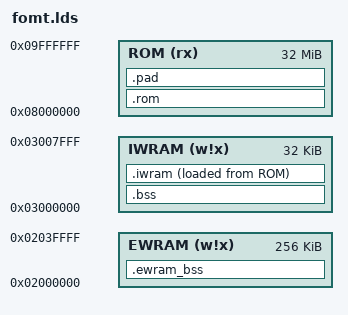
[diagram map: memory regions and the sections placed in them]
OUTPUT_ARCH(arm)

_M4aNumMusicPlayers = 5;
_M4aMaxLines = 0x50;

gMPlayJumpTableTemplate = 0x08139A88;
gScaleTable = 0x08139B18;
gFreqTable = 0x08139BCC;
gPcmSamplesPerVBlankTable = 0x08139BFC;
gCgbScaleTable = 0x08139C14;
gCgbFreqTable = 0x08139C98;
gNoiseTable = 0x08139CB0;
gCgb3Vol = 0x08139CEC;
gClockTable = 0x08139CFC;
gXcmdTable = 0x08139D30;

__15ControllerC7F58Pv = func_080C7F58;
_._15ControllerC7F58 = func_080C8360;
__vt_19LivestockController = vtable_unk_080E7D30;
func_08085584 = __19LivestockControllerPvUi;
func_0808562C = _._19LivestockController;

func_0805218C = __15SceneOwner521BCRt8SmartPtr1Z13AUnk_0800080CPv;
func_08057DD8 = __15SceneOwner57E1CRt8SmartPtr1Z13AUnk_0800080CPvUc;
func_0805CEB8 = __15SceneOwner5CEFCRt8SmartPtr1Z13AUnk_0800080CPvUc;
func_0805E624 = __15SceneOwner5E658Rt8SmartPtr1Z13AUnk_0800080CPv;
func_08069E14 = __15SceneOwner69E58Rt8SmartPtr1Z13AUnk_0800080CPvUc;
func_0805FCD0 = __15SceneOwner5FD04Rt8SmartPtr1Z13AUnk_0800080CPv;
func_080755EC = __15SceneOwner7561CRt8SmartPtr1Z13AUnk_0800080CPv;
func_0807DD38 = __15SceneOwner7DD68Rt8SmartPtr1Z13AUnk_0800080CPv;
func_0807EE14 = __15SceneOwner7EE44Rt8SmartPtr1Z13AUnk_0800080CPv;
func_0807F580 = __15SceneOwner7F5B0Rt8SmartPtr1Z13AUnk_0800080CPv;
func_0808045C = __15SceneOwner8048CRt8SmartPtr1Z13AUnk_0800080CPv;
func_08080D94 = __15SceneOwner80DC4Rt8SmartPtr1Z13AUnk_0800080CPv;
func_08081A40 = __15SceneOwner81A70Rt8SmartPtr1Z13AUnk_0800080CPv;
func_08082114 = __15SceneOwner82144Rt8SmartPtr1Z13AUnk_0800080CPv;
func_08083A7C = __15SceneOwner83AECRt8SmartPtr1Z13AUnk_0800080CPvUcUiUiUiUi;
func_080854F4 = __15SceneOwner85528Rt8SmartPtr1Z13AUnk_0800080CPv;
func_08088168 = __15SceneOwner881ACRt8SmartPtr1Z13AUnk_0800080CPvUi;
func_0808AB38 = __15SceneOwner8AB68Rt8SmartPtr1Z13AUnk_0800080CPv;
func_0808C56C = __15SceneOwner8C59CRt8SmartPtr1Z13AUnk_0800080CPv;
func_0808ECD8 = __15SceneOwner8ED08Rt8SmartPtr1Z13AUnk_0800080CPv;
func_08090E54 = __15SceneOwner90E84Rt8SmartPtr1Z13AUnk_0800080CPv;
func_080931B0 = __15SceneOwner931E0Rt8SmartPtr1Z13AUnk_0800080CPv;
func_08093A58 = __15SceneOwner93A88Rt8SmartPtr1Z13AUnk_0800080CPv;
func_0809A4D4 = __15SceneOwner9A518Rt8SmartPtr1Z13AUnk_0800080CPvUc;

__vt_15SceneOwner521BC = vtable_unk_080E7934;
func_080521BC = _._15SceneOwner521BC;
Run__15SceneOwner521BC = func_080521FC;
__vt_15SceneOwner57E1C = vtable_unk_080E7960;
func_08057E1C = _._15SceneOwner57E1C;
Run__15SceneOwner57E1C = func_08057E5C;
__vt_15SceneOwner5CEFC = vtable_unk_080E798C;
func_0805CEFC = _._15SceneOwner5CEFC;
Run__15SceneOwner5CEFC = func_0805CF3C;
__vt_15SceneOwner5E658 = vtable_unk_080E79B8;
func_0805E658 = _._15SceneOwner5E658;
Run__15SceneOwner5E658 = func_0805E698;
__vt_15SceneOwner5FD04 = vtable_unk_080E79F8;
func_0805FD04 = _._15SceneOwner5FD04;
Run__15SceneOwner5FD04 = func_0805FD44;
__vt_15SceneOwner69E58 = vtable_unk_080E7A98;
func_08069E58 = _._15SceneOwner69E58;
Run__15SceneOwner69E58 = func_08069E98;
__vt_15SceneOwner7561C = vtable_unk_080E7B4C;
func_0807561C = _._15SceneOwner7561C;
Run__15SceneOwner7561C = func_0807565C;
__vt_15SceneOwner7DD68 = vtable_unk_080E7C30;
func_0807DD68 = _._15SceneOwner7DD68;
Run__15SceneOwner7DD68 = func_0807DDA8;
__vt_15SceneOwner7EE44 = vtable_unk_080E7C4C;
func_0807EE44 = _._15SceneOwner7EE44;
Run__15SceneOwner7EE44 = func_0807EE84;
__vt_15SceneOwner7F5B0 = vtable_unk_080E7C68;
func_0807F5B0 = _._15SceneOwner7F5B0;
Run__15SceneOwner7F5B0 = func_0807F5F0;
__vt_15SceneOwner8048C = vtable_unk_080E7C84;
func_0808048C = _._15SceneOwner8048C;
Run__15SceneOwner8048C = func_080804CC;
__vt_15SceneOwner80DC4 = vtable_unk_080E7CA0;
func_08080DC4 = _._15SceneOwner80DC4;
Run__15SceneOwner80DC4 = func_08080E04;
__vt_15SceneOwner81A70 = vtable_unk_080E7CBC;
func_08081A70 = _._15SceneOwner81A70;
Run__15SceneOwner81A70 = func_08081AB0;
__vt_15SceneOwner82144 = vtable_unk_080E7CD8;
func_08082144 = _._15SceneOwner82144;
Run__15SceneOwner82144 = func_08082184;
__vt_15SceneOwner83AEC = vtable_unk_080E7D04;
func_08083AEC = _._15SceneOwner83AEC;
Run__15SceneOwner83AEC = func_08083B2C;
__vt_15SceneOwner85528 = vtable_unk_080E7D20;
func_08085528 = _._15SceneOwner85528;
Run__15SceneOwner85528 = func_08085568;
__vt_15SceneOwner881AC = vtable_unk_080E7D3C;
func_080881AC = _._15SceneOwner881AC;
Run__15SceneOwner881AC = func_080881EC;
__vt_15SceneOwner8AB68 = vtable_unk_080E7D58;
func_0808AB68 = _._15SceneOwner8AB68;
Run__15SceneOwner8AB68 = func_0808ABA8;
__vt_15SceneOwner8C59C = vtable_unk_080E7D74;
func_0808C59C = _._15SceneOwner8C59C;
Run__15SceneOwner8C59C = func_0808C5DC;
__vt_15SceneOwner8ED08 = vtable_unk_080E7D90;
func_0808ED08 = _._15SceneOwner8ED08;
Run__15SceneOwner8ED08 = func_0808ED48;
__vt_15SceneOwner90E84 = vtable_unk_080E7DAC;
func_08090E84 = _._15SceneOwner90E84;
Run__15SceneOwner90E84 = func_08090EC4;
__vt_15SceneOwner925C4 = vtable_unk_080E7DC8;
func_080925C4 = _._15SceneOwner925C4;
Run__15SceneOwner925C4 = func_08092604;
__vt_15SceneOwner931E0 = vtable_unk_080E7DE4;
func_080931E0 = _._15SceneOwner931E0;
Run__15SceneOwner931E0 = func_08093220;
__vt_15SceneOwner93A88 = vtable_unk_080E8018;
func_08093A88 = _._15SceneOwner93A88;
Run__15SceneOwner93A88 = func_08093AD4;
__vt_15SceneOwner9A518 = vtable_unk_080E824C;
func_0809A518 = _._15SceneOwner9A518;
Run__15SceneOwner9A518 = func_0809A558;

__vt_7UnkPoly = vtable_unk_080E82D8;
__vt_18MenuGlyphCacheBase = vtable_unk_080E7908;
__vt_15MenuParsePolicy = vtable_unk_080E78F0;
func_080E105C = _._22MenuGlyphCacheLifetime;
func_080E10E0 = DestroyMenuCallback;
func_080E10EC = ContinueParsing__15MenuParsePolicy;
func_080E10F0 = AcceptCommand__15MenuParsePolicy;
func_080E10F4 = StopOnBoundary__15MenuParsePolicy;
func_080E10F8 = _._15MenuParsePolicy;
func_080E1118 = RowsDirty__18MenuGlyphCacheBase;
func_080E111C = Clear__18MenuGlyphCacheBase;
func_080E1120 = Next__18MenuGlyphCacheBase;
func_080E1124 = Reset__18MenuGlyphCacheBase;
func_080E1128 = _._18MenuGlyphCacheBase;
func_080E1148 = DestroyMenuScene5143C;
func_080E118C = BuildMenuArticleName;
func_080E1498 = DestroyMenuArticleProvider;
func_080E14B8 = BuildAnimalNameText;
func_080E1824 = DestroyAnimalNameProvider;
func_080E1844 = BuildIndexedItemName;
func_080E1964 = DestroyIndexedItemNameProvider;
func_080E1984 = DestroySpriteAnimationProviderLifetime;
func_080E19A4 = BuildStoredStringName;
func_080E1A28 = DestroyStoredStringNameProvider;
func_080E1A48 = RunProviderCheck;
func_080E1A54 = CleanupLargeProvider;
func_080E1C18 = DestroyMenuDualRangeCleanup;
func_080E1D54 = DestroyMenuSingleRangeCleanup;
func_080E1DBC = CheckMenuRangeProvider;
func_080E1DC8 = ReleaseMenuRangeProvider;
func_080E1DD4 = DestroyMenuRangeOwnerE1DD4;
func_080E211C = DestroyMenuRangeOwnerE211C;
func_080E2170 = RotateMenuTreeLeft;
func_080E21A8 = RotateMenuTreeRight;
func_080E21E0 = BalanceMenuTreeAfterInsert;
func_080E2354 = PreviousMenuTreeNode;
func_080E2B5C = ReleaseMenuTreeSubtreeA;
func_080E2B88 = ReleaseMenuTreeSubtreeB;
func_080E2E78 = ReleaseMenuTreeSubtreeC;
func_080D3ED4 = DestroyMenuSimple_080d3ed4;
func_080DE220 = DestroyMenuSimple_080de220;
func_080E103C = DestroyMenuSimple_080e103c;
func_080E3D94 = DestroyMenuSimple_080e3d94;
func_080E4190 = DestroyMenuSimple_080e4190;
func_080E4544 = DestroyMenuSimple_080e4544;
func_080D6F1C = InitializeMenuPair_080d6f1c;
func_080D6F5C = InitializeMenuPair_080d6f5c;
func_080D7F60 = ReleaseMenuResource_080d7f60;
func_080D7F74 = ReleaseMenuResource_080d7f74;
func_080D7F88 = ReleaseMenuResource_080d7f88;
func_080D7AAC = DestroyMenuGlobal_080d7aac;
func_080D7B04 = DestroyMenuGlobal_080d7b04;
func_080E581C = DestroyMenuGlobal_080e581c;
func_080E5844 = DestroyMenuGlobal_080e5844;
func_080DCE60 = DestroyMenuOwner_080dce60;
func_080DCEEC = DestroyMenuOwner_080dceec;
func_080E4510 = DestroyMenuOwner_080e4510;
func_080DCE94 = DestroyMenuEntity_080dce94;
func_080DCEC0 = DestroyMenuEntity_080dcec0;
func_080DCF20 = DestroyMenuEntity_080dcf20;
func_080E35E8 = InitializeMenuSubobject_080e35e8;
func_080E3628 = InitializeMenuSubobject_080e3628;
func_080E3650 = InitializeMenuSubobject_080e3650;
func_080E3734 = InitializeMenuSubobject_080e3734;
func_080DD3A8 = EmitMenuObject_080dd3a8;
func_080DD434 = EmitMenuObject_080dd434;
func_080DD514 = EmitMenuObject_080dd514;
func_080DD5B8 = EmitMenuObject_080dd5b8;
func_080DD7B8 = EmitMenuObject_080dd7b8;
func_080DD890 = EmitMenuObject_080dd890;
func_080DDE98 = EmitMenuObject_080dde98;
func_080DDF3C = EmitMenuObject_080ddf3c;
func_080DDFE0 = EmitMenuObject_080ddfe0;
func_080DE080 = EmitMenuObject_080de080;
func_080DC57C = ReleaseTreeSubtreeDC57C;
func_080E54C4 = ReleaseTreeSubtreeE54C4;
func_08007874 = __13UnkHandleBase;
func_080079E8 = _._13UnkHandleBase;
func_0803AC78 = _._12Unk_0803AB30;
func_0803B0A8 = _._12Unk_0803AEA0;
func_080A47B4 = _._7UnkPoly;
__vt_18UnknownEntityThing = vtable_unk_080E68B4;
__vt_22UnknownEntityThingBase = vtable_unk_080E65E0;
_._18UnknownEntityThing = func_080DC8F8;
__vt_12LilliaEntity = vtable_unk_080E7198;
func_08035AFC = __12LilliaEntityP10GameObjectP3NpcUi;
func_08035B38 = vfunc_30__12LilliaEntity;

__vt_10RickEntity = vtable_unk_080E7158;
func_08035B64 = __10RickEntityP10GameObjectP3NpcUi;
func_08035B9C = vfunc_30__10RickEntity;
__vt_12PopuriEntity = vtable_unk_080E7118;
func_08035BC8 = __12PopuriEntityP10GameObjectP3NpcUi;
func_08035CD4 = vfunc_30__12PopuriEntity;
__vt_12BarleyEntity = vtable_unk_080E70D8;
func_08035D04 = __12BarleyEntityP10GameObjectP3NpcUi;
func_08035D40 = vfunc_30__12BarleyEntity;
__vt_9MayEntity = vtable_unk_080E7098;
func_08035D70 = __9MayEntityP10GameObjectP3NpcUi;
func_08035DAC = vfunc_30__9MayEntity;
__vt_13SaibaraEntity = vtable_unk_080E7058;
func_08035DD8 = __13SaibaraEntityP10GameObjectP3NpcUi;
func_08035E14 = vfunc_30__13SaibaraEntity;
__vt_10GrayEntity = vtable_unk_080E7018;
func_08035E40 = __10GrayEntityP10GameObjectP3NpcUi;
func_08035E7C = vfunc_30__10GrayEntity;
__vt_10DukeEntity = vtable_unk_080E6FD8;
func_08035EAC = __10DukeEntityP10GameObjectP3NpcUi;
func_08035EE4 = vfunc_30__10DukeEntity;
__vt_11MannaEntity = vtable_unk_080E6F98;
func_08035F10 = __11MannaEntityP10GameObjectP3NpcUi;
func_08035F48 = vfunc_30__11MannaEntity;
__vt_11BasilEntity = vtable_unk_080E6F58;
func_08035F74 = __11BasilEntityP10GameObjectP3NpcUi;
func_08035FB0 = vfunc_30__11BasilEntity;
__vt_10AnnaEntity = vtable_unk_080E6F18;
func_08035FE0 = __10AnnaEntityP10GameObjectP3NpcUi;
func_0803601C = vfunc_30__10AnnaEntity;
__vt_10MaryEntity = vtable_unk_080E6ED8;
func_08036048 = __10MaryEntityP10GameObjectP3NpcUi;
func_08036154 = vfunc_30__10MaryEntity;
__vt_12ThomasEntity = vtable_unk_080E6E98;
func_08036184 = __12ThomasEntityP10GameObjectP3NpcUi;
func_080361C0 = vfunc_30__12ThomasEntity;
__vt_12HarrisEntity = vtable_unk_080E6E58;
func_080361EC = __12HarrisEntityP10GameObjectP3NpcUi;
func_08036228 = vfunc_30__12HarrisEntity;
__vt_11EllenEntity = vtable_unk_080E6E18;
func_08036258 = __11EllenEntityP10GameObjectP3NpcUi;
func_08036290 = vfunc_30__11EllenEntity;
__vt_9StuEntity = vtable_unk_080E6DD8;
func_080362C0 = __9StuEntityP10GameObjectP3NpcUi;
func_080362FC = vfunc_30__9StuEntity;
__vt_10JeffEntity = vtable_unk_080E6D98;
func_08036328 = __10JeffEntityP10GameObjectP3NpcUi;
func_08036364 = vfunc_30__10JeffEntity;
__vt_11SashaEntity = vtable_unk_080E6D58;
func_08036390 = __11SashaEntityP10GameObjectP3NpcUi;
func_080363CC = vfunc_30__11SashaEntity;
__vt_11KarenEntity = vtable_unk_080E6D18;
func_080363F8 = __11KarenEntityP10GameObjectP3NpcUi;
func_08036500 = vfunc_30__11KarenEntity;
__vt_12DoctorEntity = vtable_unk_080E6CD8;
func_08036530 = __12DoctorEntityP10GameObjectP3NpcUi;
func_08036564 = vfunc_30__12DoctorEntity;
__vt_10ElliEntity = vtable_unk_080E6C98;
func_08036590 = __10ElliEntityP10GameObjectP3NpcUi;
func_0803669C = vfunc_30__10ElliEntity;
__vt_12CarterEntity = vtable_unk_080E6C58;
func_080366CC = __12CarterEntityP10GameObjectP3NpcUi;
func_08036704 = vfunc_30__12CarterEntity;
__vt_11CliffEntity = vtable_unk_080E6C18;
func_08036730 = __11CliffEntityP10GameObjectP3NpcUi;
func_080367C8 = vfunc_30__11CliffEntity;
__vt_10DougEntity = vtable_unk_080E6BD8;
func_080367F8 = __10DougEntityP10GameObjectP3NpcUi;
func_08036834 = vfunc_30__10DougEntity;
__vt_9AnnEntity = vtable_unk_080E6B58;
func_080368C4 = __9AnnEntityP10GameObjectP3NpcUi;
func_080369E0 = vfunc_30__9AnnEntity;
__vt_9KaiEntity = vtable_unk_080E6B18;
func_08036A10 = __9KaiEntityP10GameObjectP3NpcUi;
func_08036A4C = vfunc_30__9KaiEntity;
__vt_10GotzEntity = vtable_unk_080E6AD8;
func_08036A78 = __10GotzEntityP10GameObjectP3NpcUi;
func_08036B1C = vfunc_30__10GotzEntity;
__vt_10ZackEntity = vtable_unk_080E6A98;
func_08036B4C = __10ZackEntityP10GameObjectP3NpcUi;
func_08036B80 = vfunc_30__10ZackEntity;
__vt_9WonEntity = vtable_unk_080E6A58;
func_08036C48 = __9WonEntityP10GameObjectP3NpcUi;
func_08036C80 = vfunc_30__9WonEntity;
__vt_13GourmetEntity = vtable_unk_080E6A18;
func_08036CAC = __13GourmetEntityP10GameObjectP3NpcUi;
func_08036CDC = vfunc_30__13GourmetEntity;
__vt_20HarvestGoddessEntity = vtable_unk_080E69D8;
func_08036D0C = __20HarvestGoddessEntityP10GameObjectP3NpcUi;
func_08036D3C = vfunc_30__20HarvestGoddessEntity;
__vt_11KappaEntity = vtable_unk_080E6998;
func_08036D68 = __11KappaEntityP10GameObjectP3NpcUi;
func_08036D98 = vfunc_30__11KappaEntity;
__vt_8LuEntity = vtable_unk_080E6B98;
func_08036860 = __8LuEntityP10GameObjectP3NpcUi;
func_08036898 = vfunc_30__8LuEntity;

__vt_9LouEntity = vtable_unk_080E6958;
func_08036DC4 = __9LouEntityP10GameObjectP3NpcUi;
func_08036E00 = vfunc_30__9LouEntity;
__vt_11ChildEntity = vtable_unk_080E6918;
func_08036E2C = __11ChildEntityP10GameObjectP3NpcUi;
func_08036EF0 = vfunc_3C__11ChildEntityUi;

__vt_14UnkEntity37008 = vtable_unk_080E7328;
func_08037008 = __14UnkEntity37008P10GameObjectR13ActorLocationUiUi;
func_08037048 = _._14UnkEntity37008;
func_08037244 = SetBox__14UnkEntity37008RC3Box;
func_08037430 = vfunc_34__14UnkEntity37008;
func_08037434 = vfunc_10__14UnkEntity37008;
func_0803745C = vfunc_14__14UnkEntity37008;
func_08037470 = GetBox__C14UnkEntity37008;

__vt_13UnkEntity72E4 = vtable_unk_080E72E4;
func_0803753C = vfunc_30__13UnkEntity72E4;
__vt_13UnkEntity72A0 = vtable_unk_080E72A0;
func_080376E4 = vfunc_30__13UnkEntity72A0;
__vt_13UnkEntity725C = vtable_unk_080E725C;
func_0803788C = vfunc_30__13UnkEntity725C;
func_080378B8 = vfunc_3C__13UnkEntity725C;
func_080378EC = GetAnim__13UnkEntity725CUi;
__vt_13UnkEntity7218 = vtable_unk_080E7218;
func_080379D8 = vfunc_30__13UnkEntity7218;
func_08037A04 = vfunc_3C__13UnkEntity7218;
func_08037A38 = GetAnim__13UnkEntity7218Ui;
func_08037618 = GetAnim__13UnkEntity72E4Ui;
func_08037628 = GetSpeed__13UnkEntity72E4Ui;
func_080377C4 = GetAnim__13UnkEntity72A0Ui;
func_080377D4 = GetSpeed__13UnkEntity72A0Ui;
func_080378FC = GetSpeed__13UnkEntity725CUi;
func_08037A48 = GetSpeed__13UnkEntity7218Ui;
func_08037BB8 = __13UnkEntity7218P10GameObjectR13ActorLocation;
func_08037BE0 = __13UnkEntity725CP10GameObjectR13ActorLocation;
__vt_10BallEntity = vtable_unk_080E73B4;
func_08038028 = __10BallEntityP10GameObjectR8Location;
func_080380EC = Launch__10BallEntityUi;
func_08038108 = IsActive__C10BallEntity;
func_0803834C = GetBox__C10BallEntity;
func_0803836C = GetFlightHeight__C10BallEntity;
__vt_11Entity38740 = vtable_unk_080E7380;
__vt_11Entity398A4 = vtable_unk_080E74DC;
__vt_12Strategy74CC = vtable_unk_080E74CC;
__vt_12Strategy74BC = vtable_unk_080E74BC;
__vt_12Strategy74AC = vtable_unk_080E74AC;
__vt_12Strategy749C = vtable_unk_080E749C;
__vt_12Strategy748C = vtable_unk_080E748C;
func_08038740 = __11Entity38740P10GameObjectPv;
func_080387A0 = vfunc_30__11Entity38740;
func_080387B8 = MethodB8__11Entity38740;
func_080387C8 = MethodC8__11Entity38740;
func_080387D8 = MethodD8__11Entity38740;
func_080387EC = MethodEC__11Entity38740;
func_080387FC = MethodFC__11Entity38740;
func_0803880C = Method0C__11Entity38740;
func_0801FD0C = vfunc_3C__10GameObjectUi;
gUnk_08104258 = gCharacterInfo;

MEMORY
{
    EWRAM (w!x) : ORIGIN = 0x02000000, LENGTH = 256K
    IWRAM (w!x) : ORIGIN = 0x03000000, LENGTH = 32K
    ROM   (rx)  : ORIGIN = 0x08000000, LENGTH = 32M
}

SECTIONS
{
    .ewram_bss (NOLOAD) : ALIGN(4)
    {
        . = ALIGN(4); src/sound_data.o(.sbss);
        . = ALIGN(4); src/m4a.o(.gSoundInfo);
        . = ALIGN(4); src/m4a.o(.gMPlayJumpTable);
        . = ALIGN(4); src/m4a.o(.gCgbChans);
        . = ALIGN(4); src/m4a.o(.gMusicPlayerA);
        . = ALIGN(4); src/m4a.o(.gMusicPlayerB);
        . = ALIGN(4); src/m4a.o(.gMusicPlayerC);
        . = ALIGN(4); src/m4a.o(.gMusicPlayerE);
        . = ALIGN(4); src/m4a.o(.gMPlayMemAccArea);
        . = ALIGN(4); src/m4a.o(.gMusicPlayerD);
        __ewram_bss_end = .;
    } > EWRAM

    .bss (NOLOAD) : ALIGN(4)
    {
        . = ALIGN(4); src/m4a.o(.bss);
        . = ALIGN(4);
        . = 0x000400; gUnk_03000400 = .;
        . = 0x000402; gUnk_03000402 = .;
        . = 0x000404; gUnk_03000404 = .;
        . = 0x000408; gUnk_03000408 = .;
        . = 0x00040C; gUnk_0300040C = .;
        . = 0x000410; gUnk_03000410 = .;
        . = 0x000414; gUnk_03000414 = .;
        . = 0x000418; gUnk_03000418 = .;
        . = 0x00041C; gUnk_0300041C = .;
        . = 0x000420; gUnk_03000420 = .;
        . = 0x000430; gUnk_03000430 = .;
        . = 0x000450; gUnk_03000450 = .;
        . = 0x000490; /* end */
    } > IWRAM

    .rom : ALIGN(4)
    {
        src/crt0.o(.rom_header);
        asm/main.o(.text);
        asm/sram_proxy_1.o(.text);
        src/save_format.o(.text);
        asm/sram_proxy_1.o(.text.after_save_format);
        asm/interrupt.o(.text);
        src/new.o(.text);
        src/pure_virtual.o(.text);
        asm/sram_proxy_2.o(.text);
        src/scene.o(.text);
        asm/scene.o(.text);
        asm/intro_scene.o(.text);
        asm/new_game.o(.text);
        src/hardware.o(.text);
        asm/hardware.o(.text);
        src/resource_handle.o(.text.resource_handle_ctor);
        asm/hardware.o(.text.after_resource_handle_ctor);
        src/resource_handle.o(.text.resource_handle_dtor);
        asm/hardware.o(.text.after_resource_handle_dtor);
        src/resource_handle.o(.text.resource_handle_acquire);
        src/resource_handle.o(.text.resource_handle_ops);
        asm/hardware.o(.text.after_resource_handle_ops);
        src/resource_handle.o(.text.resource_block_reset);
        src/resource_handle.o(.text.resource_block_ranges);
        asm/hardware.o(.text.after_resource_block_reset);
        src/resource_handle.o(.text.resource_block_free);
        asm/hardware.o(.text.after_resource_block_free);
        src/hardware_context.o(.text.hardware_get_context);
        asm/hardware.o(.text.after_hardware_get_context);
        src/hardware_context.o(.text.hardware_accessors);
        asm/hardware.o(.text.after_hardware_accessors);
        src/hardware_context.o(.text.hardware_vblank_callbacks);
        asm/hardware.o(.text.after_hardware_vblank_callbacks);
        src/hardware_transfer.o(.text.hardware_transfer_setup);
        asm/hardware.o(.text.after_hardware_transfer_setup);
        src/hardware_transfer.o(.text.hardware_transfer_execute);
        asm/hardware.o(.text.after_hardware_transfer_execute);
        src/key_input.o(.text);
        asm/hardware.o(.text.after_key_input);
        src/intrusive_callback_list.o(.text.intrusive_callback_node_destroy);
        asm/hardware.o(.text.after_intrusive_callback_node_destroy);
        src/intrusive_callback_list.o(.text.intrusive_callback_list_destroy);
        asm/hardware.o(.text.after_intrusive_callback_list_destroy);
        src/intrusive_callback_list.o(.text.intrusive_callback_list_append);
        asm/hardware.o(.text.after_intrusive_callback_list_append);
        src/intrusive_callback_list.o(.text.intrusive_callback_list_remove);
        asm/hardware.o(.text.after_intrusive_callback_list_remove);
        src/intrusive_callback_list.o(.text.intrusive_callback_list_clear);
        asm/hardware.o(.text.after_intrusive_callback_list_clear);
        src/farm.o(.text);
        src/field.o(.text);
        src/shipping_bin.o(.text);
        src/tool_chest.o(.text);
        src/fridge.o(.text);
        src/shelf.o(.text);
        src/record_player.o(.text);
        src/code_0800BC58.o(.text);
        src/farm_house.o(.text);
        src/coop.o(.text);
        src/barn.o(.text);
        src/item.o(.text);
        src/code_0800E2E4.o(.text);
        src/farmer.o(.text);
        src/rucksack_item.o(.text);
        src/held_item.o(.text);
        src/rucksack.o(.text);
        asm/more_items.o(.text);
        asm/game_scene.o(.text);
        asm/game_state.o(.text);
        src/game_state_flag_setters.o(.text.game_state_flag_setters);
        asm/game_state.o(.text.after_game_state_flag_setters);
        src/save_format.o(.text.save_record);
        asm/game_state.o(.text.after_save_record);
        src/code_08017C00.o(.text);
        asm/game_state.o(.text.after_func_08017C00);
        src/code_0801A8C0.o(.text);
        asm/game_state.o(.text.after_time_period);
        src/game_object_article_interaction.o(.text);
        asm/game_state.o(.text.after_article_interaction);
        src/game_object_discard.o(.text);
        asm/game_state.o(.text.after_discarded_item);
        src/game_object_entity_lookup.o(.text);
        asm/game_state.o(.text.after_entity_lookups);
        src/entity.o(.text);
        src/code_entity_08020018.o(.text);
        asm/code_entities.o(.text);
        src/farmer_entity_item_action.o(.text);
        asm/code_entities.o(.text.after_func_0802A7E0);
        src/entity_actor.o(.text);
        asm/code_entities_080320DC.o(.text);
        src/entity_effect.o(.text);
        asm/code_entities_080320DC.o(.text.after_func_08032690);
        src/npc_entity.o(.text);
        asm/code_entities_08034CEC.o(.text);
        src/entity_lillia.o(.text);
        src/entity_resident_npcs.o(.text.npc_resident_run1);
        asm/code_entities_08034CEC.o(.text.after_npc_resident_run1);
        src/entity_resident_npcs.o(.text.npc_resident_run2);
        asm/code_entities_08034CEC.o(.text.after_npc_resident_run2);
        src/entity_resident_npcs.o(.text.npc_resident_run3);
        asm/code_entities_08034CEC.o(.text.after_npc_resident_run3);
        src/entity_resident_npcs.o(.text.npc_resident_run4);
        asm/code_entities_08034CEC.o(.text.after_npc_resident_run4);
        src/entity_resident_npcs.o(.text.npc_resident_run5);
        asm/code_entities_08034CEC.o(.text.after_npc_resident_run5);
        src/entity_resident_npcs.o(.text.npc_resident_run6);
        asm/code_entities_08034CEC.o(.text.after_npc_resident_run6);
        src/entity_resident_npcs.o(.text.npc_resident_run7);
        asm/code_entities_08034CEC.o(.text.after_npc_resident_run7);
        src/entity_resident_npcs.o(.text.npc_resident_run8);
        asm/code_entities_08034CEC.o(.text.after_npc_resident_run8);
        src/entity_resident_npcs.o(.text.npc_resident_run9);
        src/entity_resident_npcs.o(.text.npc_special_run1);
        asm/code_entities_08034CEC.o(.text.after_npc_special_run1);
        src/entity_resident_npcs.o(.text.npc_special_run2);
        asm/code_entities_08034CEC.o(.text.after_npc_special_run2);
        src/entity_unk_08037008.o(.text.entity_locbound_run1);
        asm/code_entities_08034CEC.o(.text.after_entity_locbound_run1);
        src/entity_unk_08037008.o(.text.entity_locbound_run1b);
        asm/code_entities_08034CEC.o(.text.after_entity_locbound_run1b);
        src/entity_unk_08037008.o(.text.entity_locbound_run2);
        asm/code_entities_08034CEC.o(.text.after_entity_locbound_run2);
        src/entity_unk_08037008.o(.text.entity_locbound_run3);
        asm/code_entities_08034CEC.o(.text.after_entity_locbound_run3);
        src/entity_unk_08037008.o(.text.entity_locbound_run3b);
        asm/code_entities_08034CEC.o(.text.after_entity_locbound_run3b);
        src/entity_unk_08037008.o(.text.entity_locbound_run4);
        asm/code_entities_08034CEC.o(.text.after_entity_locbound_run4);
        src/entity_unk_08037008.o(.text.entity_locbound_run4b);
        asm/code_entities_08034CEC.o(.text.after_entity_locbound_run4b);
        src/entity_unk_08037008.o(.text.entity_locbound_run5);
        asm/code_entities_08034CEC.o(.text.after_entity_locbound_run5);
        src/entity_unk_08037008.o(.text.entity_locbound_run6);
        asm/code_entities_08034CEC.o(.text.after_entity_locbound_run6);
        src/entity_unk_08037008.o(.text.entity_locbound_run8);
        asm/code_entities_08034CEC.o(.text.after_entity_locbound_run8);
        src/entity_ball.o(.text.ball_ctor);
        src/entity_ball.o(.text.ball_dtor);
        asm/code_entities_08034CEC.o(.text.after_ball_ctor);
        src/entity_ball.o(.text.ball_run1);
        asm/code_entities_08034CEC.o(.text.after_ball_run1);
        src/entity_ball.o(.text.ball_run3);
        src/entity_ball.o(.text.ball_run2);
        src/entity_ball.o(.text.ball_dog_play_position);
        asm/code_entities_08034CEC.o(.text.after_ball_run2);
        src/entity_ball.o(.text.ball_reset_dog_play);
        asm/code_entities_08034CEC.o(.text.after_ball_reset_dog_play);
        src/entity_ball.o(.text.ball_controller_update);
        asm/code_entities_08034CEC.o(.text.after_ball_controller_update);
        src/entity_unk_08038740.o(.text.entity38740_ctor);
        src/entity_unk_08038740.o(.text.entity38740_factory);
        src/entity_unk_08038740.o(.text.entity38740_b8);
        src/entity_unk_08038740.o(.text.entity38740_c8);
        src/entity_unk_08038740.o(.text.entity38740_d8);
        src/entity_unk_08038740.o(.text.entity38740_ec);
        src/entity_unk_08038740.o(.text.entity38740_fc);
        src/entity_unk_08038740.o(.text.entity38740_0c);
        asm/code_entities_08034CEC.o(.text.after_entity38740_0c);
        src/entity_unk_08038740.o(.text.entity38740_ctrl_e90);
        src/entity_unk_08038740.o(.text.entity38740_ctrl_ea0);
        src/entity_unk_08038740.o(.text.entity38740_ctrl_eb8);
        asm/code_entities_08034CEC.o(.text.after_entity38740_eb8);
        src/entity_unk_08038740.o(.text.entity38740_ctrl_390d0);
        asm/code_entities_08034CEC.o(.text.after_entity38740_390d0);
        src/entity_unk_08038740.o(.text.entity39134_nearest);
        asm/code_entities_08034CEC.o(.text.after_entity39134);
        src/entity_unk_08038740.o(.text.entity391c0_area);
        asm/code_entities_08034CEC.o(.text.after_entity391c0);
        src/entity_unk_08038740.o(.text.entity391fc_noop);
        src/entity_unk_08038740.o(.text.entity39200_false);
        asm/code_entities_08034CEC.o(.text.after_entity39200);
        src/entity_unk_08038740.o(.text.entity3930c_true);
        asm/code_entities_08034CEC.o(.text.after_entity3930c);
        src/entity_unk_08038740.o(.text.entity396f4_mode);
        asm/code_entities_08034CEC.o(.text.after_entity396f4);
        src/entity_unk_08038740.o(.text.entity398a0_two);
        asm/code_entities_08034CEC.o(.text.after_entity398a0);
        src/entity_unk_08038740.o(.text.entity398a4_ctor);
        src/entity_unk_08038740.o(.text.entity399c0_dtor);
        src/entity_unk_08038740.o(.text.entity39a30_factory);
        asm/code_entities_08034CEC.o(.text.after_entity39a30);
        src/entity_unk_08038740.o(.text.entity39a5c_noop);
        asm/code_entities_08034CEC.o(.text.after_entity39a5c);
        src/entity_unk_08038740.o(.text.entity39a60_update);
        src/entity_unk_08038740.o(.text.entity39d4c_table);
        src/entity_unk_08038740.o(.text.entity39d5c_mask);
        src/entity_unk_08038740.o(.text.entity39d98_mode);
        asm/code_entities_08034CEC.o(.text.after_entity39d98);
        src/entity_unk_08038740.o(.text.entity39da8_setup);
        src/entity_unk_08038740.o(.text.entity39e18_setup);
        asm/code_entities_08034CEC.o(.text.after_entity39e18);
        src/entity_unk_08038740.o(.text.entity39e88_two);
        src/entity_unk_08038740.o(.text.entity39e8c_strategy);
        asm/code_entities_08034CEC.o(.text.after_entity39e8c);
        src/entity_unk_08038740.o(.text.entity39f50_dtor);
        asm/code_entities_08034CEC.o(.text.after_entity39f50);
        src/entity_unk_08038740.o(.text.entity3a144_table);
        asm/code_entities_08034CEC.o(.text.after_entity3a144);
        src/entity_unk_08038740.o(.text.entity3a320_sine);
        src/entity_unk_08038740.o(.text.entity3a334_cosine);
        src/entity_unk_08038740.o(.text.entity3a350_sound);
        asm/code_entities_08034CEC.o(.text.after_entity3a350);
        src/entity_unk_08038740.o(.text.entity3a798_factory);
        src/entity_unk_08038740.o(.text.entity3a804_get_step);
        src/entity_unk_08038740.o(.text.entity3a80c_set_step);
        src/entity_unk_08038740.o(.text.entity3a814_will_finish);
        src/entity_unk_08038740.o(.text.entity3a820_is_moving);
        src/entity_unk_08038740.o(.text.entity3a840_update_effect);
        src/entity_unk_08038740.o(.text.entity3a870_set_animation);
        src/entity_unk_08038740.o(.text.entity3a8a0_game_object);

        src/map_resource.o(.text);
        asm/code_0803A8A4.o(.text.after_map_resource);
        src/resource_owner_cached.o(.text);
        asm/code_0803A8A4.o(.text.resource_owner_variable_ctor);
        src/resource_owner_variable.o(.text);
        asm/code_0803A8A4.o(.text.after_resource_owner_dtors);
        src/character_schedule.o(.text);
        asm/code_0803A8A4.o(.text.after_character_schedules);
        src/script_engine.o(.text);
        asm/code_0803EE94.o(.text);
        src/heart_event_days.o(.text);
        asm/code_0803EE94.o(.text.after_heart_event_days);
        src/menu_text.o(.text.menu_text_streams);
        asm/code_0803EE94.o(.text.after_menu_text_streams);
        src/menu_text_canvas.o(.text.menu_text_canvas);
        src/menu_tilemap.o(.text.menu_tilemap_rectangle);
        asm/code_0803EE94.o(.text.after_menu_tilemap_rectangle);
        src/menu_draw_nodes.o(.text.menu_tilemap_rect_node);
        asm/code_0803EE94.o(.text.after_menu_tilemap_rect_node);
        src/menu_draw_nodes.o(.text.menu_tilemap_wide_node);
        asm/code_0803EE94.o(.text.after_menu_tilemap_wide_node);
        src/menu_draw_nodes.o(.text.menu_tilemap_tall_node);
        asm/code_0803EE94.o(.text.after_menu_tilemap_tall_node);
        src/menu_draw_nodes.o(.text.menu_tilemap_draw_nodes);
        asm/code_0803EE94.o(.text.after_menu_tilemap_draw_nodes);
        src/menu_glyph_cache.o(.text.menu_glyph_cache_draw);
        asm/code_0803EE94.o(.text.after_menu_glyph_cache_draw);
        src/menu_glyph_cache.o(.text.menu_glyph_cache_clear);
        asm/code_0803EE94.o(.text.after_menu_glyph_cache_clear);
        src/scene_owners.o(.text.scene_ctor_5218c);
        asm/code_0803EE94.o(.text.after_scene_ctor_5218c);
        src/scene_owners.o(.text.scene_owner_521bc);
        asm/code_0803EE94.o(.text.after_scene_owner_521bc);
        src/scene_owners.o(.text.scene_run_521fc);
        asm/code_0803EE94.o(.text.after_scene_run_521fc);
        src/scene_owners.o(.text.scene_ctor_57dd8);
        asm/code_0803EE94.o(.text.after_scene_ctor_57dd8);
        src/scene_owners.o(.text.scene_owner_57e1c);
        asm/code_0803EE94.o(.text.after_scene_owner_57e1c);
        src/scene_owners.o(.text.scene_run_57e5c);
        asm/code_0803EE94.o(.text.after_scene_run_57e5c);
        src/scene_owners.o(.text.scene_ctor_5ceb8);
        asm/code_0803EE94.o(.text.after_scene_ctor_5ceb8);
        src/scene_owners.o(.text.scene_owner_5cefc);
        asm/code_0803EE94.o(.text.after_scene_owner_5cefc);
        src/scene_owners.o(.text.scene_run_5cf3c);
        asm/code_0803EE94.o(.text.after_scene_run_5cf3c);
        src/scene_owners.o(.text.scene_ctor_5e624);
        asm/code_0803EE94.o(.text.after_scene_ctor_5e624);
        src/scene_owners.o(.text.scene_owner_5e658);
        asm/code_0803EE94.o(.text.after_scene_owner_5e658);
        src/scene_owners.o(.text.scene_run_5e698);
        asm/code_0803EE94.o(.text.after_scene_run_5e698);
        src/sprite_animation_provider.o(.text);
        asm/code_0803EE94.o(.text.after_animation_provider);
        src/sprite_animation_provider.o(.text.sprite_animation_provider_counts);
        src/sprite_animator.o(.text);
        asm/code_0803EE94.o(.text.after_sprite_animator);
        src/scene_owners.o(.text.scene_ctor_5fcd0);
        asm/code_0803EE94.o(.text.after_scene_ctor_5fcd0);
        src/scene_owners.o(.text.scene_owner_5fd04);
        asm/code_0803EE94.o(.text.after_scene_owner_5fd04);
        src/scene_owners.o(.text.scene_run_5fd44);
        asm/code_0803EE94.o(.text.after_scene_run_5fd44);
        src/scene_owners.o(.text.scene_ctor_69e14);
        asm/code_0803EE94.o(.text.after_scene_ctor_69e14);
        src/scene_owners.o(.text.scene_owner_69e58);
        asm/code_0803EE94.o(.text.after_scene_owner_69e58);
        src/scene_owners.o(.text.scene_run_69e98);
        asm/code_0803EE94.o(.text.after_scene_run_69e98);
        src/scene_owners.o(.text.scene_ctor_755ec);
        asm/code_0803EE94.o(.text.after_scene_ctor_755ec);
        src/scene_owners.o(.text.scene_owner_7561c);
        asm/code_0803EE94.o(.text.after_scene_owner_7561c);
        src/scene_owners.o(.text.scene_run_7565c);
        asm/code_0803EE94.o(.text.after_scene_run_7565c);
        src/shop_catalog.o(.text.shop_desc_seed);
        asm/code_0803EE94.o(.text.after_seed_shop_desc);
        src/scene_owners.o(.text.scene_ctor_7dd38);
        asm/code_0803EE94.o(.text.after_scene_ctor_7dd38);
        src/scene_owners.o(.text.scene_owner_7dd68);
        asm/code_0803EE94.o(.text.after_scene_owner_7dd68);
        src/scene_owners.o(.text.scene_run_7dda8);
        asm/code_0803EE94.o(.text.after_scene_run_7dda8);
        src/shop_catalog.o(.text.shop_desc_supermarket);
        asm/code_0803EE94.o(.text.after_supermarket_shop_desc);
        src/shop_catalog.o(.text.shop_desc_medicine);
        asm/code_0803EE94.o(.text.after_medicine_shop_desc);
        src/scene_owners.o(.text.scene_ctor_7ee14);
        asm/code_0803EE94.o(.text.after_scene_ctor_7ee14);
        src/scene_owners.o(.text.scene_owner_7ee44);
        asm/code_0803EE94.o(.text.after_scene_owner_7ee44);
        src/scene_owners.o(.text.scene_run_7ee84);
        asm/code_0803EE94.o(.text.after_scene_run_7ee84);
        src/scene_owners.o(.text.scene_ctor_7f580);
        asm/code_0803EE94.o(.text.after_scene_ctor_7f580);
        src/scene_owners.o(.text.scene_owner_7f5b0);
        asm/code_0803EE94.o(.text.after_scene_owner_7f5b0);
        src/scene_owners.o(.text.scene_run_7f5f0);
        asm/code_0803EE94.o(.text.after_scene_run_7f5f0);
        src/shop_catalog.o(.text.shop_desc_mixed);
        asm/code_0803EE94.o(.text.after_mixed_shop_desc);
        src/scene_owners.o(.text.scene_ctor_8045c);
        asm/code_0803EE94.o(.text.after_scene_ctor_8045c);
        src/scene_owners.o(.text.scene_owner_8048c);
        asm/code_0803EE94.o(.text.after_scene_owner_8048c);
        src/scene_owners.o(.text.scene_run_804cc);
        asm/code_0803EE94.o(.text.after_scene_run_804cc);
        src/scene_owners.o(.text.scene_ctor_80d94);
        asm/code_0803EE94.o(.text.after_scene_ctor_80d94);
        src/scene_owners.o(.text.scene_owner_80dc4);
        asm/code_0803EE94.o(.text.after_scene_owner_80dc4);
        src/scene_owners.o(.text.scene_run_80e04);
        asm/code_0803EE94.o(.text.after_scene_run_80e04);
        src/shop_catalog.o(.text.shop_desc_record);
        asm/code_0803EE94.o(.text.after_record_shop_desc);
        src/scene_owners.o(.text.scene_ctor_81a40);
        asm/code_0803EE94.o(.text.after_scene_ctor_81a40);
        src/scene_owners.o(.text.scene_owner_81a70);
        asm/code_0803EE94.o(.text.after_scene_owner_81a70);
        src/scene_owners.o(.text.scene_run_81ab0);
        asm/code_0803EE94.o(.text.after_scene_run_81ab0);
        src/scene_owners.o(.text.scene_ctor_82114);
        asm/code_0803EE94.o(.text.after_scene_ctor_82114);
        src/scene_owners.o(.text.scene_owner_82144);
        asm/code_0803EE94.o(.text.after_scene_owner_82144);
        src/scene_owners.o(.text.scene_run_82184);
        asm/code_0803EE94.o(.text.after_scene_run_82184);
        src/scene_owners.o(.text.scene_ctor_83a7c);
        asm/code_0803EE94.o(.text.after_scene_ctor_83a7c);
        src/scene_owners.o(.text.scene_owner_83aec);
        asm/code_0803EE94.o(.text.after_scene_owner_83aec);
        src/scene_owners.o(.text.scene_run_83b2c);
        asm/code_0803EE94.o(.text.after_scene_run_83b2c);
        src/scene_owners.o(.text.scene_ctor_854f4);
        asm/code_0803EE94.o(.text.after_scene_ctor_854f4);
        src/scene_owners.o(.text.scene_owner_85528);
        asm/code_0803EE94.o(.text.after_scene_owner_85528);
        src/scene_owners.o(.text.scene_run_85568);
        src/livestock_controller.o(.text.livestock_controller_lifecycle);
        asm/code_0803EE94.o(.text.after_livestock_controller_lifecycle);
        src/livestock_controller.o(.text.livestock_controller_results);
        asm/code_0803EE94.o(.text.after_livestock_controller_results);
        src/livestock_controller.o(.text.livestock_controller_stats);
        asm/code_0803EE94.o(.text.after_livestock_controller_stats);
        src/scene_owners.o(.text.scene_ctor_88168);
        asm/code_0803EE94.o(.text.after_scene_ctor_88168);
        src/scene_owners.o(.text.scene_owner_881ac);
        asm/code_0803EE94.o(.text.after_scene_owner_881ac);
        src/scene_owners.o(.text.scene_run_881ec);
        asm/code_0803EE94.o(.text.after_scene_run_881ec);
        src/scene_owners.o(.text.scene_ctor_8ab38);
        asm/code_0803EE94.o(.text.after_scene_ctor_8ab38);
        src/scene_owners.o(.text.scene_owner_8ab68);
        asm/code_0803EE94.o(.text.after_scene_owner_8ab68);
        src/scene_owners.o(.text.scene_run_8aba8);
        asm/code_0803EE94.o(.text.after_scene_run_8aba8);
        src/scene_owners.o(.text.scene_ctor_8c56c);
        asm/code_0803EE94.o(.text.after_scene_ctor_8c56c);
        src/scene_owners.o(.text.scene_owner_8c59c);
        asm/code_0803EE94.o(.text.after_scene_owner_8c59c);
        src/scene_owners.o(.text.scene_run_8c5dc);
        asm/code_0803EE94.o(.text.after_scene_run_8c5dc);
        src/scene_owners.o(.text.scene_ctor_8ecd8);
        asm/code_0803EE94.o(.text.after_scene_ctor_8ecd8);
        src/scene_owners.o(.text.scene_owner_8ed08);
        asm/code_0803EE94.o(.text.after_scene_owner_8ed08);
        src/scene_owners.o(.text.scene_run_8ed48);
        asm/code_0803EE94.o(.text.after_scene_run_8ed48);
        src/scene_owners.o(.text.scene_ctor_90e54);
        asm/code_0803EE94.o(.text.after_scene_ctor_90e54);
        src/scene_owners.o(.text.scene_owner_90e84);
        asm/code_0803EE94.o(.text.after_scene_owner_90e84);
        src/scene_owners.o(.text.scene_run_90ec4);
        asm/code_0803EE94.o(.text.after_scene_run_90ec4);
        src/scene_owners.o(.text.scene_owner_925c4);
        asm/code_0803EE94.o(.text.after_scene_owner_925c4);
        src/scene_owners.o(.text.scene_run_92604);
        asm/code_0803EE94.o(.text.after_scene_run_92604);
        src/rucksack_item_render.o(.text);
        asm/code_0803EE94.o(.text.after_rucksack_item_renderer);
        src/rucksack_wrapping.o(.text);
        asm/code_0803EE94.o(.text.after_rucksack_wrapping);
        src/scene_owners.o(.text.scene_ctor_931b0);
        asm/code_0803EE94.o(.text.after_scene_ctor_931b0);
        src/scene_owners.o(.text.scene_owner_931e0);
        asm/code_0803EE94.o(.text.after_scene_owner_931e0);
        src/scene_owners.o(.text.scene_run_93220);
        asm/code_0803EE94.o(.text.after_scene_run_93220);
        src/scene_owners.o(.text.scene_ctor_93a58);
        asm/code_0803EE94.o(.text.after_scene_ctor_93a58);
        src/scene_owners.o(.text.scene_owner_93a88);
        asm/code_0803EE94.o(.text.after_scene_owner_93a88);
        src/scene_owners.o(.text.scene_run_93ad4);
        asm/code_0803EE94.o(.text.after_scene_run_93ad4);
        src/scene_owners.o(.text.scene_ctor_9a4d4);
        asm/code_0803EE94.o(.text.after_scene_ctor_9a4d4);
        src/scene_owners.o(.text.scene_owner_9a518);
        asm/code_0803EE94.o(.text.after_scene_owner_9a518);
        src/scene_owners.o(.text.scene_run_9a558);
        asm/code_0803EE94.o(.text.after_scene_run_9a558);
        src/money.o(.text);
        asm/code_0803EE94.o(.text.after_money_debit);

        src/actor.o(.text);
        src/animal.o(.text);
        src/pet.o(.text);
        src/livestock.o(.text);
        src/barn_animal.o(.text);
        src/dog.o(.text);
        src/horse.o(.text);
        src/chicken.o(.text);
        src/cow.o(.text);
        src/sheep.o(.text);
        src/code_actor_0809BFE8.o(.text);
        asm/code_actor_0809BFE8.o(.text);
        src/fishing_records.o(.text);
        src/mine_floor.o(.text);
        asm/code_actor_0809BFE8.o(.text.after_func_0809CF34);
        src/mine_floor_accessors.o(.text);
        asm/code_actor_0809BFE8.o(.text.after_mine_floor_accessors);
        src/mine_floor_content.o(.text);
        asm/code_actor_0809BFE8.o(.text.after_mine_floor_content);
        src/mine_floor_helpers.o(.text);
        asm/code_actor_0809BFE8.o(.text.after_mine_floor_helpers);
        src/mine_floor_tile_resource.o(.text);
        asm/code_actor_0809BFE8.o(.text.after_mine_floor_tile_resource);
        src/mine_floor_progress_flags.o(.text);
        asm/code_actor_0809BFE8.o(.text.after_mine_floor_progress_flags);
        src/npc.o(.text);
        src/bachelorette.o(.text);
        src/harvest_sprite.o(.text);

        asm/code_809E804.o(.text);
        src/character_info.o(.text);
        asm/code_809E804.o(.text.after_character_info);
        src/character_location.o(.text);
        asm/code_809E804.o(.text.before_character_social);
        src/character_social.o(.text);
        asm/code_809E804.o(.text.after_character_social);
        src/ground_pickup_state.o(.text.ground_pickup_state_init);
        asm/code_809E804.o(.text.after_ground_pickup_state_init);
        src/ground_pickup_state.o(.text.ground_pickup_state_durability);
        asm/code_809E804.o(.text.after_ground_pickup_state_durability);
        src/water_region.o(.text);
        src/code_080A4650.o(.text);
        src/map_data.o(.text);
        src/code_080A46AC.o(.text);
        src/code_080A480C.o(.text);
        src/code_080A4A4C.o(.text);
        src/code_080A4A94.o(.text);
        asm/code_809E804.o(.text.after_func_080A4BEC);
        src/code_080A5670.o(.text);
        src/code_080A56DC.o(.text);
        asm/code_809E804.o(.text.after_func_080A56DC);
        src/code_080A5A9C.o(.text);
        asm/code_809E804.o(.text.after_func_080A5A9C);
        src/code_080A5EA0.o(.text);
        asm/code_809E804.o(.text.after_func_080A5EA0);
        src/code_080A601C.o(.text);
        asm/code_809E804.o(.text.after_func_080A601C);
        src/code_080A6420.o(.text);
        asm/code_809E804.o(.text.after_func_080A6420);
        src/code_080A6640.o(.text);
        asm/code_809E804.o(.text.after_func_080A6640);
        src/terrain.o(.text);
        asm/code_809E804.o(.text.after_is_footprint_on_water_surface);
        src/menu_font.o(.text.menu_font_decode);
        asm/code_809E804.o(.text.after_menu_font_decode);

        src/m4a_1.o(.text);
        src/m4a.o(.text);
        asm/code_lib_syscall.o(.text);
        asm/code_lib_sram.o(.text);
        *libgcc.a:_call_via_rX.o(.text);
        /* these need to be recompiled using -mthumb-interwork */
        /* *libc.a:memcmp.o(.text); */
        /* *libc.a:memcpy.o(.text); */
        /* *libc.a:memmove.o(.text); */
        /* *libc.a:memset.o(.text); */
        /* *libc.a:strcat.o(.text); */
        /* *libc.a:strcpy.o(.text); */
        /* *libc.a:strlen.o(.text); */
        asm/code_libc_string.o(.text);

        asm/code_linkonce.o(.text.code_080D3BC0);
        src/raw_abi_thunks.o(.text.raw_thunks_d3c60);
        asm/code_linkonce.o(.text.after_raw_thunks_d3c60);
        src/menu_simple_dtors.o(.text.menu_simple_dtor_080d3ed4);
        asm/code_linkonce.o(.text.after_menu_simple_dtor_080d3ed4);
        *(.gnu.linkonce.t.__as__6AnimalRC6Animal);
        asm/code_linkonce.o(.text.code_080D68C0);
        src/resource_handle.o(.text.resource_subtree_fill_all);
        asm/code_linkonce.o(.text.after_resource_subtree_fill_all);
        src/menu_resource_helpers.o(.text.menu_pair_080d6f1c);
        asm/code_linkonce.o(.text.after_menu_helper_080d6f1c);
        src/resource_handle.o(.text.resource_subtree_clear_all);
        asm/code_linkonce.o(.text.after_resource_subtree_clear_all);
        src/menu_resource_helpers.o(.text.menu_pair_080d6f5c);
        asm/code_linkonce.o(.text.after_menu_helper_080d6f5c);
        src/resource_handle.o(.text.resource_subtree_fill);
        asm/code_linkonce.o(.text.after_resource_subtree_fill);
        src/resource_handle.o(.text.resource_subtree_clear);
        asm/code_linkonce.o(.text.after_resource_subtree_clear);
        src/resource_handle.o(.text.resource_subtree_free);
        src/resource_handle.o(.text.resource_child_free);
        src/resource_handle.o(.text.resource_entry_pool_init);
        asm/code_linkonce.o(.text.after_resource_entry_pool_init);
        src/raw_abi_thunks.o(.text.raw_thunks_d7868);
        asm/code_linkonce.o(.text.after_raw_thunks_d7868);
        src/menu_global_owner_dtors.o(.text.menu_global_dtor_080d7aac);
        asm/code_linkonce.o(.text.after_menu_global_dtor_080d7aac);
        src/menu_global_owner_dtors.o(.text.menu_global_dtor_080d7b04);
        asm/code_linkonce.o(.text.after_menu_global_dtor_080d7b04);
        src/raw_abi_thunks.o(.text.raw_thunks_d7b2c);
        asm/code_linkonce.o(.text.after_raw_thunks_d7b2c);
        *(.gnu.linkonce.t.__as__5SheepRC5Sheep);
        *(.gnu.linkonce.t.__as__3CowRC3Cow);
        *(.gnu.linkonce.t.__as__9LivestockRC9Livestock);
        *(.gnu.linkonce.t.push_back__t8FixedVec2Z12RucksackItemUl8G12RucksackItem);
        *(.gnu.linkonce.t.push_front__t8FixedVec2Z12RucksackItemUl8G12RucksackItem);
        *(.gnu.linkonce.t.push_back__t8FixedVec2Z9ToolStackUl8G9ToolStack);
        *(.gnu.linkonce.t.push_front__t8FixedVec2Z9ToolStackUl8G9ToolStack);
        asm/code_linkonce.o(.text.code_080D7CFC);
        src/menu_resource_helpers.o(.text.menu_resource_080d7f60);
        asm/code_linkonce.o(.text.after_menu_helper_080d7f60);
        src/menu_resource_helpers.o(.text.menu_resource_080d7f74);
        asm/code_linkonce.o(.text.after_menu_helper_080d7f74);
        src/menu_resource_helpers.o(.text.menu_resource_080d7f88);
        asm/code_linkonce.o(.text.after_menu_helper_080d7f88);
        src/owned_polymorphic_dtors.o(.text.owned_dtor_db2ec);
        asm/code_linkonce.o(.text.after_owned_dtor_db2ec);
        src/owned_polymorphic_dtors.o(.text.owned_dtor_db36c);
        asm/code_linkonce.o(.text.after_owned_dtor_db36c);
        src/owned_polymorphic_dtors.o(.text.owned_dtor_db3dc);
        asm/code_linkonce.o(.text.after_owned_dtor_db3dc);
        src/owned_polymorphic_dtors.o(.text.owned_dtor_db630);
        asm/code_linkonce.o(.text.after_owned_dtor_db630);
        src/owned_polymorphic_dtors.o(.text.owned_dtor_db6a4);
        asm/code_linkonce.o(.text.after_owned_dtor_db6a4);
        src/owned_polymorphic_dtors.o(.text.owned_dtor_db714);
        asm/code_linkonce.o(.text.after_owned_dtor_db714);
        src/owned_polymorphic_dtors.o(.text.owned_dtor_db784);
        asm/code_linkonce.o(.text.after_owned_dtor_db784);
        src/owned_polymorphic_dtors.o(.text.owned_dtor_db7f4);
        asm/code_linkonce.o(.text.after_owned_dtor_db7f4);
        src/owned_polymorphic_dtors.o(.text.owned_dtor_db864);
        asm/code_linkonce.o(.text.after_owned_dtor_db864);
        src/owned_polymorphic_dtors.o(.text.owned_dtor_db8d4);
        asm/code_linkonce.o(.text.after_owned_dtor_db8d4);
        src/owned_polymorphic_dtors.o(.text.owned_dtor_db944);
        asm/code_linkonce.o(.text.after_owned_dtor_db944);
        src/owned_polymorphic_dtors.o(.text.owned_dtor_db9b4);
        asm/code_linkonce.o(.text.after_owned_dtor_db9b4);
        src/owned_polymorphic_dtors.o(.text.owned_dtor_dba24);
        asm/code_linkonce.o(.text.after_owned_dtor_dba24);
        src/owned_polymorphic_dtors.o(.text.owned_dtor_dba94);
        asm/code_linkonce.o(.text.after_owned_dtor_dba94);
        src/owned_polymorphic_dtors.o(.text.owned_dtor_dbb04);
        asm/code_linkonce.o(.text.after_owned_dtor_dbb04);
        src/owned_polymorphic_dtors.o(.text.owned_dtor_dbb74);
        asm/code_linkonce.o(.text.after_owned_dtor_dbb74);
        src/owned_polymorphic_dtors.o(.text.owned_dtor_dbbe4);
        asm/code_linkonce.o(.text.after_owned_dtor_dbbe4);
        src/owned_polymorphic_dtors.o(.text.owned_dtor_dbc50);
        asm/code_linkonce.o(.text.after_owned_dtor_dbc50);
        src/owned_polymorphic_dtors.o(.text.owned_dtor_dbcc0);
        asm/code_linkonce.o(.text.after_owned_dtor_dbcc0);
        src/owned_polymorphic_dtors.o(.text.owned_dtor_dbd30);
        asm/code_linkonce.o(.text.after_owned_dtor_dbd30);
        src/owned_polymorphic_dtors.o(.text.owned_dtor_dbda0);
        asm/code_linkonce.o(.text.after_owned_dtor_dbda0);
        src/owned_polymorphic_dtors.o(.text.owned_dtor_dbe10);
        asm/code_linkonce.o(.text.after_owned_dtor_dbe10);
        src/owned_polymorphic_dtors.o(.text.owned_dtor_dbe80);
        asm/code_linkonce.o(.text.after_owned_dtor_dbe80);
        src/owned_polymorphic_dtors.o(.text.owned_dtor_dbef0);
        asm/code_linkonce.o(.text.after_owned_dtor_dbef0);
        src/owned_polymorphic_dtors.o(.text.owned_dtor_dbf60);
        asm/code_linkonce.o(.text.after_owned_dtor_dbf60);
        src/owned_polymorphic_dtors.o(.text.owned_dtor_dbfd0);
        asm/code_linkonce.o(.text.after_owned_dtor_dbfd0);
        src/owned_polymorphic_dtors.o(.text.owned_dtor_dc040);
        asm/code_linkonce.o(.text.after_owned_dtor_dc040);
        src/owned_polymorphic_dtors.o(.text.owned_dtor_dc0c0);
        asm/code_linkonce.o(.text.after_owned_dtor_dc0c0);
        src/owned_polymorphic_dtors.o(.text.owned_dtor_dc130);
        asm/code_linkonce.o(.text.after_owned_dtor_dc130);
        src/owned_polymorphic_dtors.o(.text.owned_dtor_dc1a0);
        asm/code_linkonce.o(.text.after_owned_dtor_dc1a0);
        src/owned_polymorphic_dtors.o(.text.owned_dtor_dc21c);
        asm/code_linkonce.o(.text.after_owned_dtor_dc21c);
        src/owned_polymorphic_dtors.o(.text.owned_dtor_dc404);
        asm/code_linkonce.o(.text.after_owned_dtor_dc404);
        src/owned_polymorphic_dtors.o(.text.owned_dtor_dc474);
        asm/code_linkonce.o(.text.after_owned_dtor_dc474);
        src/owned_polymorphic_dtors.o(.text.owned_dtor_dc4e4);
        asm/code_linkonce.o(.text.after_owned_dtor_dc4e4);
        src/owned_polymorphic_dtors.o(.text.owned_dtor_dc554);
        asm/code_linkonce.o(.text.after_owned_dtor_dc554);
        src/menu_tree_lifetime.o(.text.menu_tree_release_dc57c);
        asm/code_linkonce.o(.text.after_tree_release_dc57c);
        src/entity_effect_dtor.o(.text);
        asm/code_linkonce.o(.text.after_func_080DC8F8);
        src/npc_entity_dtor_thunks.o(.text.npc_entity_dtor_thunks);
        src/entity37008_dtor_thunks.o(.text.entity37008_dtor_thunks);
        asm/code_linkonce.o(.text.after_entity37008_dtor_thunks);
        src/menu_owner_dtors.o(.text.menu_owner_dtor_080dce60);
        asm/code_linkonce.o(.text.after_menu_owner_dtor_080dce60);
        src/menu_entity_dtors.o(.text.menu_entity_dtor_080dce94);
        asm/code_linkonce.o(.text.after_menu_dtor_080dce94);
        src/menu_entity_dtors.o(.text.menu_entity_dtor_080dcec0);
        asm/code_linkonce.o(.text.after_menu_dtor_080dcec0);
        src/menu_owner_dtors.o(.text.menu_owner_dtor_080dceec);
        asm/code_linkonce.o(.text.after_menu_owner_dtor_080dceec);
        src/menu_entity_dtors.o(.text.menu_entity_dtor_080dcf20);
        asm/code_linkonce.o(.text.after_menu_dtor_080dcf20);
        src/menu_emit_wrappers.o(.text.menu_emit_080dd3a8);
        asm/code_linkonce.o(.text.after_menu_emit_080dd3a8);
        src/menu_emit_wrappers.o(.text.menu_emit_080dd434);
        asm/code_linkonce.o(.text.after_menu_emit_080dd434);
        src/menu_emit_wrappers.o(.text.menu_emit_080dd514);
        asm/code_linkonce.o(.text.after_menu_emit_080dd514);
        src/menu_emit_wrappers.o(.text.menu_emit_080dd5b8);
        asm/code_linkonce.o(.text.after_menu_emit_080dd5b8);
        src/menu_emit_wrappers.o(.text.menu_emit_080dd7b8);
        asm/code_linkonce.o(.text.after_menu_emit_080dd7b8);
        src/menu_emit_wrappers.o(.text.menu_emit_080dd890);
        asm/code_linkonce.o(.text.after_menu_emit_080dd890);
        src/menu_emit_wrappers.o(.text.menu_emit_080dde98);
        asm/code_linkonce.o(.text.after_menu_emit_080dde98);
        src/menu_emit_wrappers.o(.text.menu_emit_080ddf3c);
        asm/code_linkonce.o(.text.after_menu_emit_080ddf3c);
        src/menu_emit_wrappers.o(.text.menu_emit_080ddfe0);
        asm/code_linkonce.o(.text.after_menu_emit_080ddfe0);
        src/menu_emit_wrappers.o(.text.menu_emit_080de080);
        asm/code_linkonce.o(.text.after_menu_emit_080de080);
        src/menu_simple_dtors.o(.text.menu_simple_dtor_080de220);
        asm/code_linkonce.o(.text.after_menu_simple_dtor_080de220);
        src/owned_polymorphic_dtors.o(.text.owned_dtor_e09bc);
        asm/code_linkonce.o(.text.after_owned_dtor_e09bc);
        src/raw_abi_thunks.o(.text.raw_thunks_e0a7c);
        asm/code_linkonce.o(.text.after_raw_thunks_e0a7c);
        *(.gnu.linkonce.t.__lower_bound__H4ZPC12JumpTableEntZiZ28ScriptJumpTableSearchCompareZl_X01T0RCX11X21PX31_X01);
        asm/code_linkonce.o(.text.code_080E0EF0);
        src/raw_abi_thunks.o(.text.raw_thunks_e1018);
        asm/code_linkonce.o(.text.after_raw_thunks_e1018);
        src/menu_simple_dtors.o(.text.menu_simple_dtor_080e103c);
        asm/code_linkonce.o(.text.after_menu_simple_dtor_080e103c);
        src/menu_glyph_cache_lifetime.o(.gnu.linkonce.t._._22MenuGlyphCacheLifetime);
        src/menu_glyph_cache_interfaces.o(.text.menu_callback_dtor);
        src/menu_glyph_cache_interfaces.o(.gnu.linkonce.t.ContinueParsing__15MenuParsePolicy);
        src/menu_glyph_cache_interfaces.o(.gnu.linkonce.t.AcceptCommand__15MenuParsePolicy);
        src/menu_glyph_cache_interfaces.o(.gnu.linkonce.t.StopOnBoundary__15MenuParsePolicy);
        src/menu_glyph_cache_interfaces.o(.gnu.linkonce.t._._15MenuParsePolicy);
        src/menu_glyph_cache_lifetime.o(.gnu.linkonce.t.RowsDirty__18MenuGlyphCacheBase);
        src/menu_glyph_cache_lifetime.o(.gnu.linkonce.t.Clear__18MenuGlyphCacheBase);
        src/menu_glyph_cache_lifetime.o(.gnu.linkonce.t.Next__18MenuGlyphCacheBase);
        src/menu_glyph_cache_lifetime.o(.gnu.linkonce.t.Reset__18MenuGlyphCacheBase);
        src/menu_glyph_cache_lifetime.o(.gnu.linkonce.t._._18MenuGlyphCacheBase);
        src/menu_scene_lifetime.o(.text.menu_scene_dtor_5143c);
        src/menu_glyph_cache_interfaces.o(.text.menu_article_name);
        asm/code_linkonce.o(.text.after_menu_article_name);
        src/menu_glyph_cache_interfaces.o(.text.menu_article_provider_dtor);
        src/menu_glyph_cache_interfaces.o(.text.menu_animal_name);
        asm/code_linkonce.o(.text.after_menu_animal_name);
        src/menu_name_providers.o(.text.menu_provider_dtor_e1824);
        src/menu_name_providers.o(.text.menu_indexed_item_name);
        asm/code_linkonce.o(.text.after_provider_e1844);
        src/menu_name_providers.o(.text.menu_provider_dtor_e1964);
        src/menu_name_providers.o(.text.menu_provider_dtor_e1984);
        src/menu_name_providers.o(.text.menu_stored_string_name);
        asm/code_linkonce.o(.text.after_provider_e19a4);
        src/menu_name_providers.o(.text.menu_provider_dtor_e1a28);
        src/menu_name_providers.o(.text.menu_provider_check_e1a48);
        src/menu_name_providers.o(.text.menu_provider_cleanup_e1a54);
        asm/code_linkonce.o(.text.after_provider_e1a54);
        src/menu_range_cleanups.o(.text.menu_dual_range_cleanup_e1c18);
        asm/code_linkonce.o(.text.after_range_cleanup_e1c18);
        src/menu_range_cleanups.o(.text.menu_single_range_cleanup_e1d54);
        asm/code_linkonce.o(.text.after_range_cleanup_e1d54);
        src/raw_abi_thunks.o(.text.raw_thunks_e1d8c);
        asm/code_linkonce.o(.text.after_raw_thunks_e1d8c);
        src/menu_name_providers.o(.text.menu_range_check_e1dbc);
        src/menu_name_providers.o(.text.menu_range_release_e1dc8);
        asm/code_linkonce.o(.text.after_menu_range_provider_callbacks_e1dc8);
        src/menu_range_owner_lifetime.o(.text.menu_owner_cleanup_e1dd4);
        asm/code_linkonce.o(.text.after_menu_owner_e1dd4);
        src/raw_abi_thunks.o(.text.raw_thunks_e20f8);
        asm/code_linkonce.o(.text.after_raw_thunks_e20f8);
        src/menu_range_owner_lifetime.o(.text.menu_owner_cleanup_e211c);
        src/menu_tree_rotations.o(.text);
        asm/code_linkonce.o(.text.after_menu_owner_e211c);
        src/menu_tree_balance.o(.text.menu_tree_insert_balance_e21e0);
        asm/code_linkonce.o(.text.after_menu_tree_insert_balance_e21e0);
        src/menu_tree_balance.o(.text.menu_tree_prev_e2354);
        asm/code_linkonce.o(.text.after_menu_tree_prev_e2354);
        src/menu_tree_lifetime.o(.text.menu_tree_release_a_e2b5c);
        src/menu_tree_lifetime.o(.text.menu_tree_release_b_e2b88);
        asm/code_linkonce.o(.text.after_menu_tree_release_e2b88);
        src/menu_tree_lifetime.o(.text.menu_tree_release_c_e2e78);
        asm/code_linkonce.o(.text.after_menu_tree_release_e2e78);
        src/owned_polymorphic_dtors.o(.text.owned_dtor_e34dc);
        asm/code_linkonce.o(.text.after_owned_dtor_e34dc);
        src/menu_subobject_initializers.o(.text.menu_subobject_init_080e35e8);
        asm/code_linkonce.o(.text.after_menu_init_080e35e8);
        src/menu_subobject_initializers.o(.text.menu_subobject_init_080e3628);
        asm/code_linkonce.o(.text.after_menu_init_080e3628);
        src/menu_subobject_initializers.o(.text.menu_subobject_init_080e3650);
        asm/code_linkonce.o(.text.after_menu_init_080e3650);
        src/menu_subobject_initializers.o(.text.menu_subobject_init_080e3734);
        asm/code_linkonce.o(.text.after_menu_init_080e3734);
        src/menu_simple_dtors.o(.text.menu_simple_dtor_080e3d94);
        asm/code_linkonce.o(.text.after_menu_simple_dtor_080e3d94);
        src/menu_simple_dtors.o(.text.menu_simple_dtor_080e4190);
        asm/code_linkonce.o(.text.after_menu_simple_dtor_080e4190);
        src/owned_polymorphic_dtors.o(.text.owned_dtor_e41e8);
        asm/code_linkonce.o(.text.after_owned_dtor_e41e8);
        src/owned_polymorphic_dtors.o(.text.owned_dtor_e4210);
        asm/code_linkonce.o(.text.after_owned_dtor_e4210);
        src/menu_owner_dtors.o(.text.menu_owner_dtor_080e4510);
        asm/code_linkonce.o(.text.after_menu_owner_dtor_080e4510);
        src/menu_simple_dtors.o(.text.menu_simple_dtor_080e4544);
        asm/code_linkonce.o(.text.after_menu_simple_dtor_080e4544);
        src/menu_tree_lifetime.o(.text.menu_tree_release_e54c4);
        asm/code_linkonce.o(.text.after_tree_release_e54c4);
        src/menu_global_owner_dtors.o(.text.menu_global_dtor_080e581c);
        asm/code_linkonce.o(.text.after_menu_global_dtor_080e581c);
        src/menu_global_owner_dtors.o(.text.menu_global_dtor_080e5844);
        asm/code_linkonce.o(.text.after_menu_global_dtor_080e5844);

        *(.gnu.linkonce.d.__vt_6AScene);
        *(.gnu.linkonce.d.__vt_13AUnk_0800080C);
        . = ALIGN(4); asm/vtables.o(.rodata);
        *(.gnu.linkonce.d.__vt_7AEntity);
        . = ALIGN(4); asm/vtables.o(.rodata.080E6284);
        src/entity_effect_vtable.o(.rodata);
        asm/vtables.o(.rodata.after_vtable_unk_080E68B4);
        *(.gnu.linkonce.d.__vt_13AScriptEngine);
        . = ALIGN(4); asm/vtables.o(.rodata.080E7824);

        . = ALIGN(4); asm/data/data_080E8610.o(.rodata);
        src/data_field_weather_rates.o(.rodata);
        asm/data/data_080E8610.o(.rodata.after_field_weather_rates);
        src/shipping_bin.o(.rodata);
        src/record_player.o(.rodata);
        . = ALIGN(4); src/item.o(.rodata);
        /* . = ALIGN(4); src/code_0800E2E4.o(.rodata); */
        . = ALIGN(4); asm/data/data_080F0348.o(.rodata);
        . = ALIGN(4); src/data_schedules.o(.rodata);
        . = ALIGN(4); asm/data/data_080F1A80.o(.rodata);
        . = ALIGN(4); src/script_engine.o(.rodata);
        . = ALIGN(4); asm/data/data_080F9EB8.o(.rodata);
        src/data_shop_catalog.o(.rodata.shop_catalog_fddd8);
        asm/data/data_080F9EB8.o(.rodata.after_seed_catalog);
        src/data_shop_catalog.o(.rodata.shop_catalog_fdfa4);
        asm/data/data_080F9EB8.o(.rodata.after_supermarket_catalog);
        src/data_shop_catalog.o(.rodata.shop_catalog_fe050);
        asm/data/data_080F9EB8.o(.rodata.after_medicine_catalog);
        src/data_shop_catalog.o(.rodata.shop_catalog_fe484);
        asm/data/data_080F9EB8.o(.rodata.after_mixed_catalog);
        src/data_shop_catalog.o(.rodata.shop_catalog_fe740);
        asm/data/data_080F9EB8.o(.rodata.after_winery_catalog);
        src/data_shop_catalog.o(.rodata.shop_catalog_fe8fc);
        asm/data/data_080F9EB8.o(.rodata.after_record_article_catalog);
        src/data_shop_catalog.o(.rodata.livestock_shop_ffb90);
        asm/data/data_080F9EB8.o(.rodata.after_livestock_shop_catalog);
        src/data_livestock_day_update_info.o(.rodata);
        src/data_cursed_tool_requirements.o(.rodata);
        asm/data/data_080F9EB8.o(.rodata.after_cursed_tool_requirements);
        src/data_character_info.o(.rodata);
        asm/data/data_080F9EB8.o(.rodata.after_character_info);
        src/data_water_regions.o(.rodata);
        asm/data/data_080F9EB8.o(.rodata.after_water_regions);
        . = ALIGN(4); src/sound_data.o(.rodata.*);
        . = ALIGN(4); asm/data/data_0813B288.o(.rodata);
    } > ROM = 0xFF

    .iwram : ALIGN(4)
    {
        asm/code_iwram.o(.iwram);
    } > IWRAM AT> ROM = 0xFF

    __iwram_vma     = ADDR(.iwram);
    __iwram_vma_end = ADDR(.iwram) + SIZEOF(.iwram);
    __iwram_lma     = LOADADDR(.iwram);

    .pad : ALIGN(4)
    {
        LONG(0);
        . = 0x08800000 - 0x0875C240;
    } > ROM = 0xFF

    /* DWARF 2 sections */
    .debug_aranges  0 : { *(.debug_aranges) }
    .debug_pubnames 0 : { *(.debug_pubnames) }
    .debug_info     0 : { *(.debug_info) }
    .debug_abbrev   0 : { *(.debug_abbrev) }
    .debug_line     0 : { *(.debug_line) }
    .debug_frame    0 : { *(.debug_frame) }
    .debug_str      0 : { *(.debug_str) }
    .debug_loc      0 : { *(.debug_loc) }
    .debug_macinfo  0 : { *(.debug_macinfo) }

    /* Discard everything not specifically mentioned above. */
    /DISCARD/ :
    {
        *(*);
    }
}
